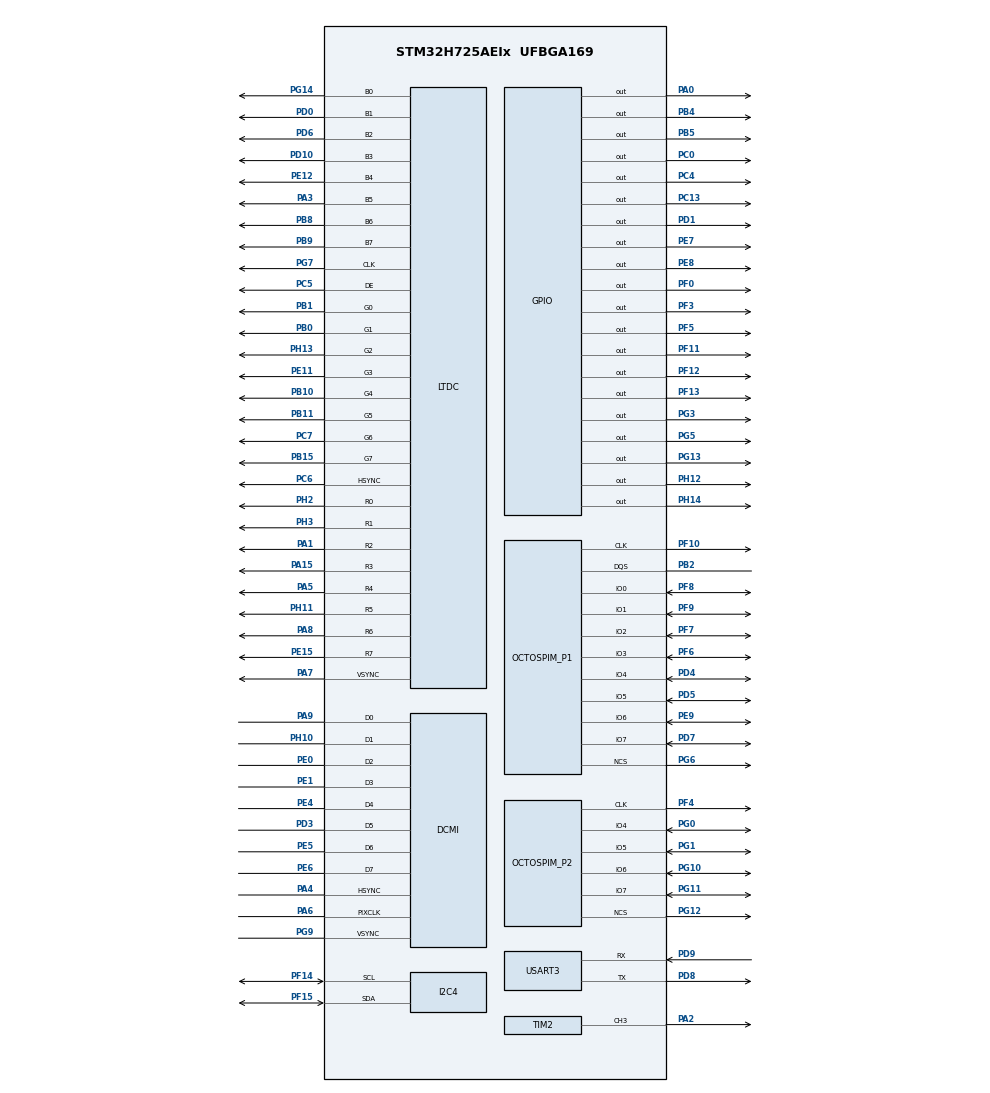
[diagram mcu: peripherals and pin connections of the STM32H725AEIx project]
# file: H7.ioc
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PD7.Mode=OCTOSPI1_IOH_Port1H
PF5.GPIO_PuPd=GPIO_PULLUP
IWDG1.Prescaler=IWDG_PRESCALER_32
PF4.Mode=O2_P2_CLK
PH0-OSC_IN.Signal=RCC_OSC_IN
PH12.Signal=GPIO_Output
Dma.DCMI_PSSI.0.PeriphBurst=DMA_PBURST_SINGLE
PB10.Mode=RGB888
PG0.Signal=OCTOSPIM_P2_IO4
PE8.GPIO_PuPd=GPIO_PULLUP
CORTEX_M7.TypeExtField-Cortex_Memory_Protection_Unit_Region0_Settings=MPU_TEX_LEVEL2
OCTOSPI2.ClkChipSelectHighTime=0
RCC.PLLFRACN=0
Dma.DCMI_PSSI.0.Direction=DMA_PERIPH_TO_MEMORY
PC5.Mode=RGB888
PG13.Signal=GPIO_Output
PG6.Mode=OCTOSPI1_Port1_NCS
Dma.DCMI_PSSI.0.MemInc=DMA_MINC_ENABLE
LTDC.Red=255
RCC.SYSCLKSource=RCC_SYSCLKSOURCE_PLLCLK
VP_OCTOSPI2_VS_quad.Mode=quad_mode
IWDG1.Reload=500
USART3.VirtualMode-Asynchronous=VM_ASYNC
OCTOSPI1.ChipSelectBoundary=10
CORTEX_M7.Enable-Cortex_Memory_Protection_Unit_Region0_Settings=MPU_REGION_ENABLE
OCTOSPI2.DeviceSize=24
PA4.Mode=Slave_8_bits_External_Synchro
PF7.Signal=OCTOSPIM_P1_IO2
TIM2.Pulse-PWM\ Generation3\ CH3=5
I2C4.Timing=0x60404E72
PD4.Signal=OCTOSPIM_P1_IO4
PC7.Signal=LTDC_G6
PD0.Signal=LTDC_B1
PD8.Signal=USART3_TX
PE5.Signal=DCMI_D6
PE1.Signal=DCMI_D3
PB2.Signal=OCTOSPIM_P1_DQS
RCC.DIVM3=25
Dma.DCMI_PSSI.0.PeriphInc=DMA_PINC_DISABLE
RCC.DIVM2=25
RCC.DIVM1=2
DCMI.PCKPolarity=DCMI_PCKPOLARITY_RISING
PG14.Mode=RGB888
LTDC.PixelFormat_L0=LTDC_PIXEL_FORMAT_RGB565
PE9.Signal=OCTOSPIM_P1_IO6
OCTOSPI1.SampleShifting=HAL_OSPI_SAMPLE_SHIFTING_NONE
PA8.Signal=LTDC_R6
PF8.Mode=OCTOSPI1_IOL_Port1L
PF3.Signal=GPIO_Output
PH14.GPIO_PuPd=GPIO_PULLUP
PD3.Mode=Slave_8_bits_External_Synchro
LTDC.HSync=1
PA0.Signal=GPIO_Output
Dma.DCMI_PSSI.0.MemBurst=DMA_MBURST_SINGLE
PB9.Signal=LTDC_B7
Mcu.Package=UFBGA169
TIM2.Prescaler=0
PB1.Signal=LTDC_G0
RCC.PLL3FRACN=0
PH11.Mode=RGB888
LTDC.Green=0
PF3.GPIO_PuPd=GPIO_PULLUP
PE9.Mode=OCTOSPI1_IOH_Port1H
PH2.Signal=LTDC_R0
PD4.Mode=OCTOSPI1_IOH_Port1H
LTDC.VSync=1
RCC.APB4Freq_Value=137500000
OCTOSPI1.Refresh=0
PF14.Signal=I2C4_SCL
VP_DMA2D_VS_DMA2D.Mode=DMA2D_Activate
PF10.Mode=O1_P1_CLK
PF9.GPIO_PuPd=GPIO_NOPULL
RCC.SupplySource=PWR_DIRECT_SMPS_SUPPLY
CORTEX_M7.IsBufferable-Cortex_Memory_Protection_Unit_Region0_Settings=MPU_ACCESS_BUFFERABLE
PA5.Mode=RGB888
PG12.Signal=OCTOSPIM_P2_NCS
PE12.Mode=RGB888
OCTOSPI2.FifoThreshold=4
Dma.DCMI_PSSI.0.Mode=DMA_CIRCULAR
RCC.DIVQ1=11
PH13.Signal=LTDC_G2
PG5.Signal=GPIO_Output
PG9.Signal=DCMI_VSYNC
PC13.Signal=GPIO_Output
PD3.Signal=DCMI_D5
CORTEX_M7.IsCacheable-Cortex_Memory_Protection_Unit_Region0_Settings=MPU_ACCESS_CACHEABLE
PE1.Mode=Slave_8_bits_External_Synchro
PG9.Mode=Slave_8_bits_External_Synchro
PC6.Signal=LTDC_HSYNC
PD7.Signal=OCTOSPIM_P1_IO7
PD1.Signal=GPIO_Output
RCC.DIVP1=1
PD1.GPIO_PuPd=GPIO_PULLUP
NVIC.DMA2_Stream1_IRQn=true\:0\:0\:false\:false\:true\:false\:true
PC0.Signal=GPIO_Output
PC14-OSC32_IN.Signal=RCC_OSC32_IN
PD6.Mode=RGB888
PB4(NJTRST).Signal=GPIO_Output
PG10.Signal=OCTOSPIM_P2_IO6
LTDC.ImageWidth_L0=800
PD10.Signal=LTDC_B3
PA3.Mode=RGB888
PB11.Mode=RGB888
PC6.Mode=RGB888
PA9.Signal=DCMI_D0
RCC.DIVN3=55
RCC.DIVN2=266
RCC.DIVN1=44
CORTEX_M7.BaseAddress-Cortex_Memory_Protection_Unit_Region0_Settings=0x90000000
PD8.Mode=Asynchronous
PB10.Signal=LTDC_G4
DCMI.JPEGMode=DCMI_JPEG_DISABLE
PA5.Signal=LTDC_R4
PF13.GPIO_PuPd=GPIO_PULLUP
PA1.Mode=RGB888
LTDC.Blue_L0=0
PE6.Mode=Slave_8_bits_External_Synchro
PE15.Signal=LTDC_R7
PE8.Signal=GPIO_Output
CORTEX_M7.AccessPermission-Cortex_Memory_Protection_Unit_Region0_Settings=MPU_REGION_FULL_ACCESS
PF13.Signal=GPIO_Output
TIM2.Period=10
OCTOSPI1.FifoThreshold=4
PA4.Signal=DCMI_HSYNC
OCTOSPI1.MemoryType=HAL_OSPI_MEMTYPE_APMEMORY
PB5.Signal=GPIO_Output
NVIC.DCMI_PSSI_IRQn=true\:5\:0\:true\:false\:true\:true\:true
PB5.GPIO_PuPd=GPIO_PULLUP
PG11.Mode=OCTOSPI2_IOL_Port2H
LTDC.Alpha_L0=255
ProjectManager.HeapSize=0x200
PB1.Mode=RGB888
PF6.Mode=OCTOSPI1_IOL_Port1L
PF9.Signal=OCTOSPIM_P1_IO1
OCTOSPI1.DelayBlockBypass=HAL_OSPI_DELAY_BLOCK_USED
NVIC.PriorityGroup=NVIC_PRIORITYGROUP_4
OCTOSPI1.FreeRunningClock=HAL_OSPI_FREERUNCLK_DISABLE
PB8.Mode=RGB888
PF12.GPIO_PuPd=GPIO_PULLUP
TIM2.AutoReloadPreload=TIM_AUTORELOAD_PRELOAD_ENABLE
PA8.Mode=RGB888
PF4.Signal=OCTOSPIM_P2_CLK
PA15(JTDI).Mode=RGB888
RCC.DIVR2=1
PB0.Signal=LTDC_G1
LTDC.Alpha0_L0=0
PE15.Mode=RGB888
Mcu.Family=STM32H7
LTDC.BlendingFactor1_L0=LTDC_BLENDING_FACTOR1_PAxCA
Dma.DCMI_PSSI.0.EventEnable=DISABLE
PA6.Mode=Slave_8_bits_External_Synchro
VP_OCTOSPI1_VS_octo.Mode=octo_mode
RCC.CortexFreq_Value=550000000
Dma.DCMI_PSSI.0.MemDataAlignment=DMA_MDATAALIGN_WORD
PG6.Signal=OCTOSPIM_P1_NCS
PH14.Signal=GPIO_Output
PH10.Signal=DCMI_D1
RCC.HPRE=RCC_HCLK_DIV2
PA15(JTDI).Signal=LTDC_R3
OCTOSPI1.DeviceSize=23
LTDC.HBP=46
Dma.DCMI_PSSI.0.SignalID=NONE
RCC.PLL2FRACN=0
Dma.DCMI_PSSI.0.SyncPolarity=HAL_DMAMUX_SYNC_NO_EVENT
PB11.Signal=LTDC_G5
PB15.Signal=LTDC_G7
LTDC.PCPolarity=LTDC_PCPOLARITY_IPC
PD9.Mode=Asynchronous
PG11.Signal=OCTOSPIM_P2_IO7
ProjectManager.StackSize=0x400
PG3.GPIO_PuPd=GPIO_NOPULL
PH3.Mode=RGB888
Dma.DCMI_PSSI.0.RequestNumber=1
Dma.DCMI_PSSI.0.Priority=DMA_PRIORITY_VERY_HIGH
OCTOSPI1.ClockPrescaler=2
PE11.Mode=RGB888
LTDC.Blue=0
IWDG1.Window=4095
PF11.GPIO_PuPd=GPIO_PULLUP
RCC.HCLKFreq_Value=275000000
PH10.Mode=Slave_8_bits_External_Synchro
LTDC.WindowX1_L0=800
PF12.Signal=GPIO_Output
PD10.Mode=RGB888
PG5.GPIO_PuPd=GPIO_PULLUP
PH0-OSC_IN.Mode=HSE-External-Oscillator
PD5.Mode=OCTOSPI1_IOH_Port1H
PG13.GPIO_PuPd=GPIO_PULLUP
VP_IWDG1_VS_IWDG.Mode=IWDG_Activate
LTDC.VBP=23
PF9.Mode=OCTOSPI1_IOL_Port1L
PC14-OSC32_IN.Mode=LSE-External-Oscillator
Dma.DCMI_PSSI.0.SyncRequestNumber=1
PG1.Mode=OCTOSPI2_IOL_Port2H
OCTOSPI1.ChipSelectHighTime=1
PF11.Signal=GPIO_Output
LTDC.Red_L0=0
LTDC.HFP=22
LTDC.BlendingFactor2_L0=LTDC_BLENDING_FACTOR2_PAxCA
PE4.Mode=Slave_8_bits_External_Synchro
DMA2D.ColorMode=DMA2D_OUTPUT_RGB565
LTDC.ActiveW=800
PE4.Signal=DCMI_D4
CORTEX_M7.DisableExec-Cortex_Memory_Protection_Unit_Region0_Settings=MPU_INSTRUCTION_ACCESS_ENABLE
PF15.Mode=I2C
RCC.APB3Freq_Value=137500000
Dma.DCMI_PSSI.0.PeriphDataAlignment=DMA_PDATAALIGN_WORD
PH1-OSC_OUT.Mode=HSE-External-Oscillator
PA6.Signal=DCMI_PIXCLK
RCC.D1PPRE=RCC_APB3_DIV2
PA0.GPIO_PuPd=GPIO_PULLUP
OCTOSPI2.DelayBlockBypass=HAL_OSPI_DELAY_BLOCK_BYPASSED
PF8.Signal=OCTOSPIM_P1_IO0
Dma.DCMI_PSSI.0.FIFOMode=DMA_FIFOMODE_ENABLE
PF5.Signal=GPIO_Output
OCTOSPI2.ClockPrescaler=2
PF0.Signal=GPIO_Output
PC5.Signal=LTDC_DE
PE7.Signal=GPIO_Output
PH2.Mode=RGB888
PC0.GPIO_PuPd=GPIO_PULLUP
PD6.Signal=LTDC_B2
Dma.Request0=DCMI_PSSI
Dma.DCMI_PSSI.0.Instance=DMA2_Stream1
Dma.DCMI_PSSI.0.FIFOThreshold=DMA_FIFO_THRESHOLD_FULL
PA3.Signal=LTDC_B5
RCC.PLLSourceVirtual=RCC_PLLSOURCE_HSE
PC15-OSC32_OUT.Mode=LSE-External-Oscillator
NVIC.LTDC_IRQn=true\:0\:0\:true\:false\:true\:true\:true
LTDC.FBStartAdress_L0=0x90000000
OCTOSPI1.ClockMode=HAL_OSPI_CLOCK_MODE_0
CORTEX_M7.CPU_ICache=Enabled
LTDC.VFP=22
LTDC.WindowY1_L0=480
PG7.Signal=LTDC_CLK
PA7.Mode=RGB888
PH11.Signal=LTDC_R5
PG3.Signal=GPIO_Output
PC4.GPIO_PuPd=GPIO_PULLUP
PG1.Signal=OCTOSPIM_P2_IO5
PG10.Mode=OCTOSPI2_IOL_Port2H
PC4.Signal=GPIO_Output
RCC.D2PPRE2=RCC_APB2_DIV2
RCC.D2PPRE1=RCC_APB1_DIV2
PD5.Signal=OCTOSPIM_P1_IO5
PD9.Signal=USART3_RX
Dma.DCMI_PSSI.0.Polarity=HAL_DMAMUX_REQ_GEN_RISING
Dma.DCMI_PSSI.0.SyncSignalID=NONE
PF7.Mode=OCTOSPI1_IOL_Port1L
CORTEX_M7.MPU_Control=MPU_PRIVILEGED_DEFAULT
PA9.Mode=Slave_8_bits_External_Synchro
OCTOSPI1.ClkChipSelectHighTime=1
PF6.Signal=OCTOSPIM_P1_IO3
ProjectManager.TargetToolchain=STM32CubeIDE
DCMI.CaptureRate=DCMI_CR_ALL_FRAME
LTDC.ActiveH=480
PB9.Mode=RGB888
DMA2D.RedBlueSwapForeground=DMA2D_RB_REGULAR
PB4(NJTRST).GPIO_PuPd=GPIO_PULLUP
RCC.USBFreq_Value=50000000
PH13.Mode=RGB888
PG7.Mode=RGB888
PE11.Signal=LTDC_G3
PC15-OSC32_OUT.Signal=RCC_OSC32_OUT
PA1.Signal=LTDC_R2
PG14.Signal=LTDC_B0
OCTOSPI1.DelayHoldQuarterCycle=HAL_OSPI_DHQC_ENABLE
PB0.Mode=RGB888
board=custom
PG12.Mode=OCTOSPI2_Port2_NCS
PB15.Mode=RGB888
DCMI.ByteSelectMode=DCMI_BSM_ALL
RCC.APB2Freq_Value=137500000
OCTOSPI2.ChipSelectBoundary=0
LTDC.Layers=0
VP_TIM2_VS_ClockSourceINT.Mode=Internal
SH.S_TIM2_CH3.0=TIM2_CH3,PWM Generation3 CH3
PF10.Signal=OCTOSPIM_P1_CLK
PF14.Mode=I2C
PE5.Mode=Slave_8_bits_External_Synchro
CORTEX_M7.IsShareable-Cortex_Memory_Protection_Unit_Region0_Settings=MPU_ACCESS_NOT_SHAREABLE
RCC.ADCFreq_Value=133000000
TIM2.Channel-PWM\ Generation3\ CH3=TIM_CHANNEL_3
PH1-OSC_OUT.Signal=RCC_OSC_OUT
PF15.Signal=I2C4_SDA
Dma.DCMI_PSSI.0.SyncEnable=DISABLE
PE6.Signal=DCMI_D7
Mcu.Name=STM32H725AEIx
PE0.Signal=DCMI_D2
PD0.Mode=RGB888
CORTEX_M7.Size-Cortex_Memory_Protection_Unit_Region0_Settings=MPU_REGION_SIZE_8MB
PE12.Signal=LTDC_B4
PA2.Signal=S_TIM2_CH3
PG0.Mode=OCTOSPI2_IOL_Port2H
RCC.SYSCLKFreq_VALUE=550000000
PB2.Mode=OCTOSPI1_Port1_DQS
RCC.QSPICLockSelection=RCC_OSPICLKSOURCE_PLL2
LTDC.Green_L0=0
PH3.Signal=LTDC_R1
PB8.Signal=LTDC_B6
RCC.D3PPRE=RCC_APB4_DIV2
CORTEX_M7.CPU_DCache=Enabled
PC7.Mode=RGB888
RCC.APB1Freq_Value=137500000
LTDC.ImageHeight_L0=480
DMA2D.Mode=DMA2D_M2M
PE0.Mode=Slave_8_bits_External_Synchro
PA7.Signal=LTDC_VSYNC

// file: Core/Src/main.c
/* USER CODE BEGIN Header */
/**
  ******************************************************************************
  * @file           : main.c
  * @brief          : Main program body
  ******************************************************************************
  * @attention
  *
  * <h2><center>&copy; Copyright (c) 2021 STMicroelectronics.
  * All rights reserved.</center></h2>
  *
  * This software component is licensed by ST under BSD 3-Clause license,
  * the "License"; You may not use this file except in compliance with the
  * License. You may obtain a copy of the License at:
  *                        opensource.org/licenses/BSD-3-Clause
  *
  ******************************************************************************
  */
/* USER CODE END Header */
#include "main.h"
#include "dcmi.h"
#include "dma.h"
#include "dma2d.h"
#include "i2c.h"
#include "iwdg.h"
#include "ltdc.h"
#include "octospi.h"
#include "tim.h"
#include "usart.h"
#include "gpio.h"

/* USER CODE BEGIN Includes */
#include "W25Q128JVSIQ.h"
#include "AP6408L.h"
#include "LOG.h"
#include "LCD.h"
#include "ov2640.h"
/* USER CODE END Includes */

void SystemClock_Config(void);
void PeriphCommonClock_Config(void);
static void MPU_Config(void);

/* USER CODE BEGIN 0 */
static Frame_TypeDef frame = {
		.buffer = OCTOSPI1_BASE,
		.length = 800*480*2,
		.width  = 800,
		.height = 480
};
static OV2640_TypeDef OV2640 = {
		.dcmi = &hdcmi,
		.dma = &hdma_dcmi_pssi,
		.i2c = &hi2c4,
		.frame = &frame
};

/* USER CODE END 0 */

int main(void)
{

  /* MPU Configuration--------------------------------------------------------*/
  MPU_Config();

  /* Enable I-Cache---------------------------------------------------------*/
  SCB_EnableICache();

  /* Enable D-Cache---------------------------------------------------------*/
  SCB_EnableDCache();

  /* MCU Configuration--------------------------------------------------------*/

  /* Reset of all peripherals, Initializes the Flash interface and the Systick. */
  HAL_Init();

  /* Configure the system clock */
  SystemClock_Config();

/* Configure the peripherals common clocks */
  PeriphCommonClock_Config();

  /* Initialize all configured peripherals */
  MX_GPIO_Init();
  MX_DMA_Init();
  MX_USART3_UART_Init();
  MX_OCTOSPI1_Init();
  MX_LTDC_Init();
  MX_OCTOSPI2_Init();
  MX_DMA2D_Init();
  MX_DCMI_Init();
  MX_I2C4_Init();
  MX_IWDG1_Init();
  MX_TIM2_Init();
  /* USER CODE BEGIN 2 */
  HAL_TIM_PWM_Start(&htim2, TIM_CHANNEL_3);
  HAL_IWDG_Refresh(&hiwdg1);
  DLYB_OCTOSPI1_Calibration(1);		/*校验延迟模块*/
  HAL_IWDG_Refresh(&hiwdg1);
  Psram_Set_DQS(Half);				/*设置PSRAM的DQS信号参数*/
  HAL_Delay(100);

  HAL_IWDG_Refresh(&hiwdg1);
  EnableMemMapped();
  HAL_Delay(200);
  HAL_IWDG_Refresh(&hiwdg1);
  /* USER CODE END 2 */

  /* Infinite loop */
  /* USER CODE BEGIN WHILE */

#if 1	/*启动OV2640传输数据*/
  OV2640_Init(&OV2640);
  OV2640_ReadID(&(OV2640.ID));
  LOG("ID: %02X %02X \r\n", OV2640.ID.PIDH, OV2640.ID.PIDL);
  OV2640_UXGAConfig();
  OV2640_Start();
#endif

  while (1)
  {
    /* USER CODE END WHILE */

    /* USER CODE BEGIN 3 */
	  HAL_GPIO_WritePin(GPIOC, GPIO_PIN_13, GPIO_PIN_RESET);
	  HAL_GPIO_WritePin(GPIOF, GPIO_PIN_0, GPIO_PIN_SET);
	  HAL_Delay(500);
	  HAL_GPIO_WritePin(GPIOC, GPIO_PIN_13, GPIO_PIN_SET);
	  HAL_GPIO_WritePin(GPIOF, GPIO_PIN_0, GPIO_PIN_RESET);
	  HAL_Delay(500);
  }
  /* USER CODE END 3 */
}

void SystemClock_Config(void)
{
  RCC_OscInitTypeDef RCC_OscInitStruct = {0};
  RCC_ClkInitTypeDef RCC_ClkInitStruct = {0};

  /** Supply configuration update enable
  */
  HAL_PWREx_ConfigSupply(PWR_DIRECT_SMPS_SUPPLY);
  /** Configure the main internal regulator output voltage
  */
  __HAL_PWR_VOLTAGESCALING_CONFIG(PWR_REGULATOR_VOLTAGE_SCALE0);

  while(!__HAL_PWR_GET_FLAG(PWR_FLAG_VOSRDY)) {}
  /** Macro to configure the PLL clock source
  */
  __HAL_RCC_PLL_PLLSOURCE_CONFIG(RCC_PLLSOURCE_HSE);
  /** Initializes the RCC Oscillators according to the specified parameters
  * in the RCC_OscInitTypeDef structure.
  */
  RCC_OscInitStruct.OscillatorType = RCC_OSCILLATORTYPE_LSI|RCC_OSCILLATORTYPE_HSE;
  RCC_OscInitStruct.HSEState = RCC_HSE_ON;
  RCC_OscInitStruct.LSIState = RCC_LSI_ON;
  RCC_OscInitStruct.PLL.PLLState = RCC_PLL_ON;
  RCC_OscInitStruct.PLL.PLLSource = RCC_PLLSOURCE_HSE;
  RCC_OscInitStruct.PLL.PLLM = 2;
  RCC_OscInitStruct.PLL.PLLN = 44;
  RCC_OscInitStruct.PLL.PLLP = 1;
  RCC_OscInitStruct.PLL.PLLQ = 11;
  RCC_OscInitStruct.PLL.PLLR = 2;
  RCC_OscInitStruct.PLL.PLLRGE = RCC_PLL1VCIRANGE_3;
  RCC_OscInitStruct.PLL.PLLVCOSEL = RCC_PLL1VCOWIDE;
  RCC_OscInitStruct.PLL.PLLFRACN = 0;
  if (HAL_RCC_OscConfig(&RCC_OscInitStruct) != HAL_OK)
  {
    Error_Handler();
  }
  /** Initializes the CPU, AHB and APB buses clocks
  */
  RCC_ClkInitStruct.ClockType = RCC_CLOCKTYPE_HCLK|RCC_CLOCKTYPE_SYSCLK
                              |RCC_CLOCKTYPE_PCLK1|RCC_CLOCKTYPE_PCLK2
                              |RCC_CLOCKTYPE_D3PCLK1|RCC_CLOCKTYPE_D1PCLK1;
  RCC_ClkInitStruct.SYSCLKSource = RCC_SYSCLKSOURCE_PLLCLK;
  RCC_ClkInitStruct.SYSCLKDivider = RCC_SYSCLK_DIV1;
  RCC_ClkInitStruct.AHBCLKDivider = RCC_HCLK_DIV2;
  RCC_ClkInitStruct.APB3CLKDivider = RCC_APB3_DIV2;
  RCC_ClkInitStruct.APB1CLKDivider = RCC_APB1_DIV2;
  RCC_ClkInitStruct.APB2CLKDivider = RCC_APB2_DIV2;
  RCC_ClkInitStruct.APB4CLKDivider = RCC_APB4_DIV2;

  if (HAL_RCC_ClockConfig(&RCC_ClkInitStruct, FLASH_LATENCY_3) != HAL_OK)
  {
    Error_Handler();
  }
}

void PeriphCommonClock_Config(void)
{
  RCC_PeriphCLKInitTypeDef PeriphClkInitStruct = {0};

  /** Initializes the peripherals clock
  */
  PeriphClkInitStruct.PeriphClockSelection = RCC_PERIPHCLK_OSPI;
  PeriphClkInitStruct.PLL2.PLL2M = 25;
  PeriphClkInitStruct.PLL2.PLL2N = 266;
  PeriphClkInitStruct.PLL2.PLL2P = 2;
  PeriphClkInitStruct.PLL2.PLL2Q = 2;
  PeriphClkInitStruct.PLL2.PLL2R = 1;
  PeriphClkInitStruct.PLL2.PLL2RGE = RCC_PLL2VCIRANGE_0;
  PeriphClkInitStruct.PLL2.PLL2VCOSEL = RCC_PLL2VCOMEDIUM;
  PeriphClkInitStruct.PLL2.PLL2FRACN = 0;
  PeriphClkInitStruct.OspiClockSelection = RCC_OSPICLKSOURCE_PLL2;
  if (HAL_RCCEx_PeriphCLKConfig(&PeriphClkInitStruct) != HAL_OK)
  {
    Error_Handler();
  }
}

/* MPU Configuration */

void MPU_Config(void)
{
  MPU_Region_InitTypeDef MPU_InitStruct = {0};

  /* Disables the MPU */
  HAL_MPU_Disable();
  /** Initializes and configures the Region and the memory to be protected
  */
  MPU_InitStruct.Enable = MPU_REGION_ENABLE;
  MPU_InitStruct.Number = MPU_REGION_NUMBER0;
  MPU_InitStruct.BaseAddress = 0x90000000;
  MPU_InitStruct.Size = MPU_REGION_SIZE_8MB;
  MPU_InitStruct.SubRegionDisable = 0x0;
  MPU_InitStruct.TypeExtField = MPU_TEX_LEVEL2;
  MPU_InitStruct.AccessPermission = MPU_REGION_FULL_ACCESS;
  MPU_InitStruct.DisableExec = MPU_INSTRUCTION_ACCESS_ENABLE;
  MPU_InitStruct.IsShareable = MPU_ACCESS_NOT_SHAREABLE;
  MPU_InitStruct.IsCacheable = MPU_ACCESS_CACHEABLE;
  MPU_InitStruct.IsBufferable = MPU_ACCESS_BUFFERABLE;

  HAL_MPU_ConfigRegion(&MPU_InitStruct);
  /* Enables the MPU */
  HAL_MPU_Enable(MPU_PRIVILEGED_DEFAULT);

}

void Error_Handler(void)
{
  /* USER CODE BEGIN Error_Handler_Debug */
  /* User can add his own implementation to report the HAL error return state */
  __disable_irq();
  while (1)
  {
	  LOG("err Handler\r\n");
	  HAL_Delay(100);
  }
  /* USER CODE END Error_Handler_Debug */
}

/************************ (C) COPYRIGHT STMicroelectronics *****END OF FILE****/
